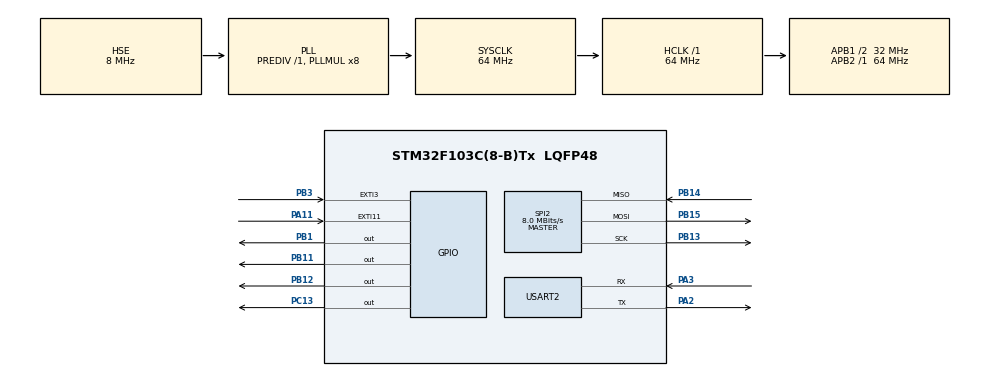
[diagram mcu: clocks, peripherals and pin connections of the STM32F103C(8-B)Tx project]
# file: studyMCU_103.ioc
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ADC1.Channel-1\#ChannelRegularConversion=ADC_CHANNEL_TEMPSENSOR
ADC1.EnableAnalogWatchDog=false
ADC1.NbrOfConversion=1
ADC1.NbrOfConversionFlag=1
ADC1.Rank-1\#ChannelRegularConversion=1
ADC1.SamplingTime-1\#ChannelRegularConversion=ADC_SAMPLETIME_28CYCLES_5
ADC1.master=1
Mcu.Family=STM32F1
Mcu.Name=STM32F103C(8-B)Tx
Mcu.Package=LQFP48
NVIC.EXTI15_10_IRQn=true\:1\:0\:true\:false\:true\:true\:true\:true
NVIC.EXTI3_IRQn=true\:0\:0\:false\:false\:true\:true\:true\:true
NVIC.PriorityGroup=NVIC_PRIORITYGROUP_4
NVIC.TIM1_UP_IRQn=true\:2\:0\:true\:false\:true\:true\:true\:true
NVIC.TIM2_IRQn=true\:2\:0\:true\:false\:true\:true\:true\:true
NVIC.TIM3_IRQn=true\:1\:0\:true\:false\:true\:true\:true\:true
NVIC.TIM4_IRQn=true\:0\:0\:false\:false\:true\:true\:true\:true
NVIC.USART2_IRQn=true\:0\:0\:false\:false\:true\:true\:true\:true
PA11.GPIO_ModeDefaultEXTI=GPIO_MODE_IT_FALLING
PA11.GPIO_PuPd=GPIO_PULLUP
PA11.Signal=GPXTI11
PA13.Mode=Serial_Wire
PA13.Signal=SYS_JTMS-SWDIO
PA14.Mode=Serial_Wire
PA14.Signal=SYS_JTCK-SWCLK
PA2.Mode=Asynchronous
PA2.Signal=USART2_TX
PA3.Mode=Asynchronous
PA3.Signal=USART2_RX
PB1.GPIO_Speed=GPIO_SPEED_FREQ_HIGH
PB1.PinState=GPIO_PIN_SET
PB1.Signal=GPIO_Output
PB11.GPIO_Speed=GPIO_SPEED_FREQ_HIGH
PB11.PinState=GPIO_PIN_SET
PB11.Signal=GPIO_Output
PB12.GPIO_Speed=GPIO_SPEED_FREQ_HIGH
PB12.PinState=GPIO_PIN_SET
PB12.Signal=GPIO_Output
PB13.GPIO_Speed=GPIO_SPEED_FREQ_MEDIUM
PB13.Mode=Full_Duplex_Master
PB13.Signal=SPI2_SCK
PB14.GPIO_PuPd=GPIO_NOPULL
PB14.Mode=Full_Duplex_Master
PB14.Signal=SPI2_MISO
PB15.GPIO_Mode=GPIO_MODE_AF_PP
PB15.GPIO_Speed=GPIO_SPEED_FREQ_MEDIUM
PB15.Mode=Full_Duplex_Master
PB15.Signal=SPI2_MOSI
PB3.GPIO_ModeDefaultEXTI=GPIO_MODE_IT_FALLING
PB3.GPIO_PuPd=GPIO_PULLUP
PB3.Signal=GPXTI3
PC13-TAMPER-RTC.GPIO_Speed=GPIO_SPEED_FREQ_MEDIUM
PC13-TAMPER-RTC.PinState=GPIO_PIN_SET
PC13-TAMPER-RTC.Signal=GPIO_Output
PD0-OSC_IN.Mode=HSE-External-Oscillator
PD0-OSC_IN.Signal=RCC_OSC_IN
PD1-OSC_OUT.Mode=HSE-External-Oscillator
PD1-OSC_OUT.Signal=RCC_OSC_OUT
ProjectManager.HeapSize=0x200
ProjectManager.StackSize=0x400
ProjectManager.TargetToolchain=Makefile
RCC.ADCPresc=RCC_ADCPCLK2_DIV8
RCC.AHBFreq_Value=64000000
RCC.APB1CLKDivider=RCC_HCLK_DIV2
RCC.APB1Freq_Value=32000000
RCC.APB1TimFreq_Value=64000000
RCC.APB2Freq_Value=64000000
RCC.APB2TimFreq_Value=64000000
RCC.HCLKFreq_Value=64000000
RCC.PLLMUL=RCC_PLL_MUL8
RCC.PLLSourceVirtual=RCC_PLLSOURCE_HSE
RCC.SYSCLKFreq_VALUE=64000000
RCC.SYSCLKSource=RCC_SYSCLKSOURCE_PLLCLK
RCC.USBFreq_Value=64000000
SPI2.BaudRatePrescaler=SPI_BAUDRATEPRESCALER_4
SPI2.CLKPhase=SPI_PHASE_2EDGE
SPI2.CLKPolarity=SPI_POLARITY_HIGH
SPI2.CalculateBaudRate=8.0 MBits/s
SPI2.Direction=SPI_DIRECTION_2LINES
SPI2.Mode=SPI_MODE_MASTER
SPI2.VirtualType=VM_MASTER
TIM1.Period=49999
TIM1.Prescaler=6399
TIM2.Period=49999
TIM2.Prescaler=6399
TIM3.Period=19999
TIM3.Prescaler=639
TIM4.Period=49
TIM4.Prescaler=63
USART2.VirtualMode=VM_ASYNC
VP_ADC1_TempSens_Input.Mode=IN-TempSens
VP_CRC_VS_CRC.Mode=CRC_Activate
VP_TIM1_VS_ClockSourceINT.Mode=Internal
VP_TIM2_VS_ClockSourceINT.Mode=Internal
VP_TIM3_VS_ClockSourceINT.Mode=Internal
VP_TIM4_VS_ClockSourceINT.Mode=Internal
board=custom

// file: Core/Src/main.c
/* USER CODE BEGIN Header */
/**
 ******************************************************************************
 * @file           : main.c
 * @brief          : Main program body
 ******************************************************************************
 * @attention
 *
 * Copyright (c) 2024 STMicroelectronics.
 * All rights reserved.
 *
 * This software is licensed under terms that can be found in the LICENSE file
 * in the root directory of this software component.
 * If no LICENSE file comes with this software, it is provided AS-IS.
 *
 ******************************************************************************
 */
/* USER CODE END Header */
#include "main.h"
#include "adc.h"
#include "crc.h"
#include "spi.h"
#include "tim.h"
#include "usart.h"
#include "gpio.h"

/* USER CODE BEGIN Includes */
#include "mb.h"
#include "mbport.h"
#include "user_mb_app.h"
#include "ReceiveTransmit.h"

#include "Flash.h"
#include "Flash_io.h"
/* USER CODE END Includes */

/* USER CODE BEGIN PTD */
static memoryChip memoryDevice;
extern uint16_t usSRegHoldBuf[];
/* USER CODE END PTD */

void SystemClock_Config(void);

int main(void)
{

  /* MCU Configuration--------------------------------------------------------*/

  /* Reset of all peripherals, Initializes the Flash interface and the Systick. */
  HAL_Init();

  /* Configure the system clock */
  SystemClock_Config();

  /* Initialize all configured peripherals */
  MX_GPIO_Init();
  MX_SPI2_Init();
  MX_USART2_UART_Init();
  MX_TIM1_Init();
  MX_TIM2_Init();
  MX_TIM3_Init();
  MX_TIM4_Init();
  MX_ADC1_Init();
  MX_CRC_Init();
  /* USER CODE BEGIN 2 */

  HAL_TIM_Base_Start_IT(&htim1);
  HAL_TIM_Base_Start_IT(&htim2);
  HAL_TIM_Base_Start_IT(&htim3);

  // uint8_t deviceId = readFlashData(0x0801FC00);
  // uint32_t BaudRate = readFlashData(0x0801FC04);

  eMBInit(MB_RTU, 1, &huart2, 19200, &htim4);
  eMBEnable();

  /* USER CODE END 2 */

  /* Infinite loop */
  /* USER CODE BEGIN WHILE */
  while (1)
  {
    eMBPoll();
    /* USER CODE END WHILE */

  }
}

void SystemClock_Config(void)
{
  RCC_OscInitTypeDef RCC_OscInitStruct = {0};
  RCC_ClkInitTypeDef RCC_ClkInitStruct = {0};
  RCC_PeriphCLKInitTypeDef PeriphClkInit = {0};

  /** Initializes the RCC Oscillators according to the specified parameters
  * in the RCC_OscInitTypeDef structure.
  */
  RCC_OscInitStruct.OscillatorType = RCC_OSCILLATORTYPE_HSE;
  RCC_OscInitStruct.HSEState = RCC_HSE_ON;
  RCC_OscInitStruct.HSEPredivValue = RCC_HSE_PREDIV_DIV1;
  RCC_OscInitStruct.HSIState = RCC_HSI_ON;
  RCC_OscInitStruct.PLL.PLLState = RCC_PLL_ON;
  RCC_OscInitStruct.PLL.PLLSource = RCC_PLLSOURCE_HSE;
  RCC_OscInitStruct.PLL.PLLMUL = RCC_PLL_MUL8;
  if (HAL_RCC_OscConfig(&RCC_OscInitStruct) != HAL_OK)
  {
    Error_Handler();
  }

  /** Initializes the CPU, AHB and APB buses clocks
  */
  RCC_ClkInitStruct.ClockType = RCC_CLOCKTYPE_HCLK|RCC_CLOCKTYPE_SYSCLK
                              |RCC_CLOCKTYPE_PCLK1|RCC_CLOCKTYPE_PCLK2;
  RCC_ClkInitStruct.SYSCLKSource = RCC_SYSCLKSOURCE_PLLCLK;
  RCC_ClkInitStruct.AHBCLKDivider = RCC_SYSCLK_DIV1;
  RCC_ClkInitStruct.APB1CLKDivider = RCC_HCLK_DIV2;
  RCC_ClkInitStruct.APB2CLKDivider = RCC_HCLK_DIV1;

  if (HAL_RCC_ClockConfig(&RCC_ClkInitStruct, FLASH_LATENCY_2) != HAL_OK)
  {
    Error_Handler();
  }
  PeriphClkInit.PeriphClockSelection = RCC_PERIPHCLK_ADC;
  PeriphClkInit.AdcClockSelection = RCC_ADCPCLK2_DIV8;
  if (HAL_RCCEx_PeriphCLKConfig(&PeriphClkInit) != HAL_OK)
  {
    Error_Handler();
  }
}

void Error_Handler(void)
{
  __disable_irq();
  while (1)
  {
  }
}
